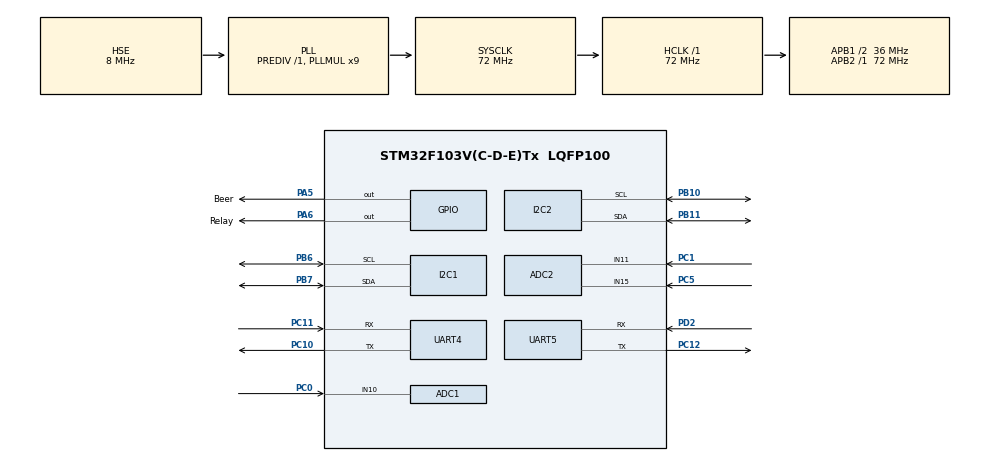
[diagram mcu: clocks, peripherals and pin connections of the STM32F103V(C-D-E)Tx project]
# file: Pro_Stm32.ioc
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ADC1.Channel-1\#ChannelRegularConversion=ADC_CHANNEL_10
ADC1.NbrOfConversionFlag=1
ADC1.Rank-1\#ChannelRegularConversion=1
ADC1.SamplingTime-1\#ChannelRegularConversion=ADC_SAMPLETIME_1CYCLE_5
ADC1.master=1
ADC2.Channel-0\#ChannelRegularConversion=ADC_CHANNEL_15
ADC2.NbrOfConversionFlag=1
ADC2.Rank-0\#ChannelRegularConversion=1
ADC2.SamplingTime-0\#ChannelRegularConversion=ADC_SAMPLETIME_1CYCLE_5
Mcu.Family=STM32F1
Mcu.Name=STM32F103V(C-D-E)Tx
Mcu.Package=LQFP100
NVIC.I2C1_EV_IRQn=true\:0\:0\:false\:false\:true\:true\:true
NVIC.I2C2_EV_IRQn=true\:0\:0\:false\:false\:true\:true\:true
NVIC.PriorityGroup=NVIC_PRIORITYGROUP_4
NVIC.UART4_IRQn=true\:0\:0\:false\:false\:true\:true\:true
NVIC.UART5_IRQn=true\:0\:0\:false\:false\:true\:true\:true
OSC_IN.Mode=HSE-External-Oscillator
OSC_IN.Signal=RCC_OSC_IN
OSC_OUT.Mode=HSE-External-Oscillator
OSC_OUT.Signal=RCC_OSC_OUT
PA13.Mode=Serial_Wire
PA13.Signal=SYS_JTMS-SWDIO
PA14.Mode=Serial_Wire
PA14.Signal=SYS_JTCK-SWCLK
PA5.GPIO_Label=Beer
PA5.Signal=GPIO_Output
PA6.GPIO_Label=Relay
PA6.Signal=GPIO_Output
PB10.Mode=I2C
PB10.Signal=I2C2_SCL
PB11.Mode=I2C
PB11.Signal=I2C2_SDA
PB6.Mode=I2C
PB6.Signal=I2C1_SCL
PB7.Mode=I2C
PB7.Signal=I2C1_SDA
PC0.Signal=ADCx_IN10
PC1.Signal=ADCx_IN11
PC10.Mode=Asynchronous
PC10.Signal=UART4_TX
PC11.Mode=Asynchronous
PC11.Signal=UART4_RX
PC12.Mode=Asynchronous
PC12.Signal=UART5_TX
PC5.Signal=ADCx_IN15
PD2.Mode=Asynchronous
PD2.Signal=UART5_RX
ProjectManager.HeapSize=0x200
ProjectManager.StackSize=0x400
ProjectManager.TargetToolchain=Makefile
RCC.ADCPresc=RCC_ADCPCLK2_DIV8
RCC.AHBFreq_Value=72000000
RCC.APB1CLKDivider=RCC_HCLK_DIV2
RCC.APB1Freq_Value=36000000
RCC.APB1TimFreq_Value=72000000
RCC.APB2Freq_Value=72000000
RCC.APB2TimFreq_Value=72000000
RCC.HCLKFreq_Value=72000000
RCC.PLLMUL=RCC_PLL_MUL9
RCC.PLLSourceVirtual=RCC_PLLSOURCE_HSE
RCC.SYSCLKFreq_VALUE=72000000
RCC.SYSCLKSource=RCC_SYSCLKSOURCE_PLLCLK
RCC.USBFreq_Value=72000000
SH.ADCx_IN10.0=ADC1_IN10,IN10
SH.ADCx_IN11.0=ADC2_IN11,IN11
SH.ADCx_IN15.0=ADC2_IN15,IN15
UART4.VirtualMode=Asynchronous
UART5.VirtualMode=Asynchronous
board=custom

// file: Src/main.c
/* USER CODE BEGIN Header */
/**
  ******************************************************************************
  * @file           : main.c
  * @brief          : Main program body
  ******************************************************************************
  * @attention
  *
  * <h2><center>&copy; Copyright (c) 2020 STMicroelectronics.
  * All rights reserved.</center></h2>
  *
  * This software component is licensed by ST under BSD 3-Clause license,
  * the "License"; You may not use this file except in compliance with the
  * License. You may obtain a copy of the License at:
  *                        opensource.org/licenses/BSD-3-Clause
  *
  ******************************************************************************
  */
/* USER CODE END Header */

#include "main.h"
#include "adc.h"
#include "i2c.h"
#include "usart.h"
#include "gpio.h"
#include "oled_i2c.h"

void SystemClock_Config(void);

/* USER CODE BEGIN 0 */
static uint8_t crc16_data[] = { 0x01, 0x04, 0x00, 0x00, 0x00, 0x0A, 0x70, 0x0d};
/* USER CODE END 0 */

int main(void)
{
  /* USER CODE BEGIN 1 */
  uint32_t adc1_val = 0x00;
  uint32_t adc2_val = 0x00;
  /* USER CODE END 1 */

  /* MCU Configuration--------------------------------------------------------*/

  /* Reset of all peripherals, Initializes the Flash interface and the Systick. */
  HAL_Init();

  /* Configure the system clock */
  SystemClock_Config();

  /* Initialize all configured peripherals */
  MX_GPIO_Init();
  MX_ADC1_Init();
  MX_ADC2_Init();
  MX_I2C1_Init();
  MX_I2C2_Init();
  MX_UART4_Init();
  MX_UART5_Init();
  /* USER CODE BEGIN 2 */
  OLED_Init();
  display_ctrl(&hi2c1,0,NULL);
  display_ctrl(&hi2c2,0,NULL);

  /* USER CODE END 2 */

  /* Infinite loop */
  while (1)
  {
    /* USER CODE BEGIN 3 */
    HAL_UART_Transmit(&huart4, crc16_data, 8, 100);
    adc1_val = MMX_ADC_Conversion(&hadc1);
    display_ctrl(&hi2c1,adc1_val,uart_data1);

    HAL_UART_Transmit(&huart5, crc16_data, 8, 100);
    adc2_val = MMX_ADC_Conversion(&hadc2);
    display_ctrl(&hi2c2,adc2_val,uart_data2);
    //HAL_Delay(1000);
  }
  /* USER CODE END 3 */
}

void SystemClock_Config(void)
{
  RCC_OscInitTypeDef RCC_OscInitStruct = {0};
  RCC_ClkInitTypeDef RCC_ClkInitStruct = {0};
  RCC_PeriphCLKInitTypeDef PeriphClkInit = {0};

  /** Initializes the CPU, AHB and APB busses clocks
  */
  RCC_OscInitStruct.OscillatorType = RCC_OSCILLATORTYPE_HSE;
  RCC_OscInitStruct.HSEState = RCC_HSE_ON;
  RCC_OscInitStruct.HSEPredivValue = RCC_HSE_PREDIV_DIV1;
  RCC_OscInitStruct.HSIState = RCC_HSI_ON;
  RCC_OscInitStruct.PLL.PLLState = RCC_PLL_ON;
  RCC_OscInitStruct.PLL.PLLSource = RCC_PLLSOURCE_HSE;
  RCC_OscInitStruct.PLL.PLLMUL = RCC_PLL_MUL9;
  if (HAL_RCC_OscConfig(&RCC_OscInitStruct) != HAL_OK)
  {
    Error_Handler();
  }
  /** Initializes the CPU, AHB and APB busses clocks
  */
  RCC_ClkInitStruct.ClockType = RCC_CLOCKTYPE_HCLK|RCC_CLOCKTYPE_SYSCLK
                              |RCC_CLOCKTYPE_PCLK1|RCC_CLOCKTYPE_PCLK2;
  RCC_ClkInitStruct.SYSCLKSource = RCC_SYSCLKSOURCE_PLLCLK;
  RCC_ClkInitStruct.AHBCLKDivider = RCC_SYSCLK_DIV1;
  RCC_ClkInitStruct.APB1CLKDivider = RCC_HCLK_DIV2;
  RCC_ClkInitStruct.APB2CLKDivider = RCC_HCLK_DIV1;

  if (HAL_RCC_ClockConfig(&RCC_ClkInitStruct, FLASH_LATENCY_2) != HAL_OK)
  {
    Error_Handler();
  }
  PeriphClkInit.PeriphClockSelection = RCC_PERIPHCLK_ADC;
  PeriphClkInit.AdcClockSelection = RCC_ADCPCLK2_DIV8;
  if (HAL_RCCEx_PeriphCLKConfig(&PeriphClkInit) != HAL_OK)
  {
    Error_Handler();
  }
}

void Error_Handler(void)
{
}

/************************ (C) COPYRIGHT STMicroelectronics *****END OF FILE****/
